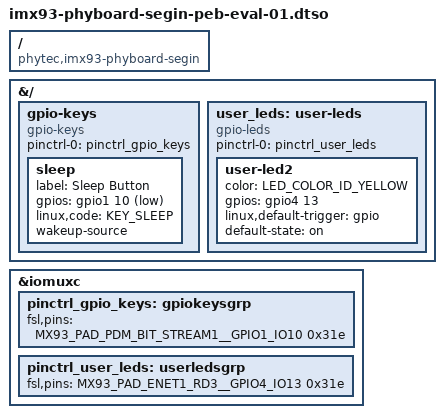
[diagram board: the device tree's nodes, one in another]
// SPDX-License-Identifier: GPL-2.0
/*
 * Copyright (C) 2023 PHYTEC Messtechnik GmbH
 * Author: Andrej Picej <andrej.picej@norik.com>
 */

#include <dt-bindings/gpio/gpio.h>
#include <dt-bindings/leds/common.h>
#include <dt-bindings/input/input.h>
#include "imx93-pinfunc.h"

/dts-v1/;
/plugin/;

/ {
	compatible = "phytec,imx93-phyboard-segin";
};

&{/} {
	gpio-keys {
		compatible = "gpio-keys";
		pinctrl-names = "default";
		pinctrl-0 = <&pinctrl_gpio_keys>;

		sleep {
			label = "Sleep Button";
			gpios = <&gpio1 10 GPIO_ACTIVE_LOW>;
			linux,code = <KEY_SLEEP>;
			wakeup-source;
		};
	};

	user_leds: user-leds {
		compatible = "gpio-leds";
		pinctrl-names = "default";
		pinctrl-0 = <&pinctrl_user_leds>;

		user-led2 {
			color = <LED_COLOR_ID_YELLOW>;
			gpios = <&gpio4 13 GPIO_ACTIVE_HIGH>;
			linux,default-trigger = "gpio";
			default-state = "on";
		};
	};
};

&iomuxc {
	pinctrl_gpio_keys: gpiokeysgrp {
		fsl,pins = <
			MX93_PAD_PDM_BIT_STREAM1__GPIO1_IO10	0x31e
		>;
	};

	pinctrl_user_leds: userledsgrp {
		fsl,pins = <
			MX93_PAD_ENET1_RD3__GPIO4_IO13		0x31e
		>;
	};
};
